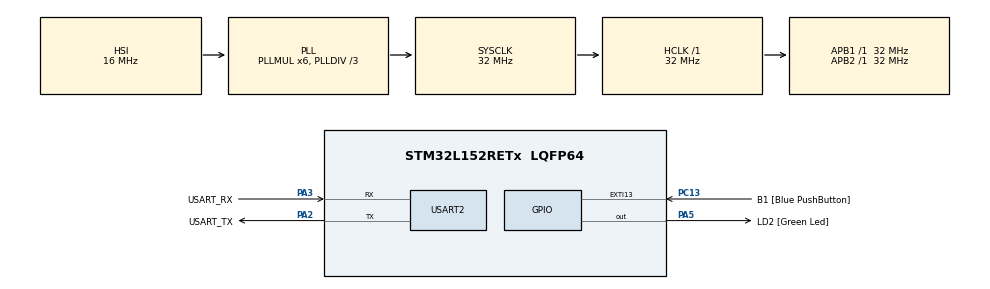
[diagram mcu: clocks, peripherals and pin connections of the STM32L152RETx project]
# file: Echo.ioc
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Mcu.Family=STM32L1
Mcu.Name=STM32L152RETx
Mcu.Package=LQFP64
NVIC.PriorityGroup=NVIC_PRIORITYGROUP_0
PA13.GPIO_Label=TMS
PA13.Mode=Serial_Wire
PA13.Signal=SYS_JTMS-SWDIO
PA14.GPIO_Label=TCK
PA14.Mode=Serial_Wire
PA14.Signal=SYS_JTCK-SWCLK
PA2.GPIO_Label=USART_TX
PA2.Mode=Asynchronous
PA2.Signal=USART2_TX
PA3.GPIO_Label=USART_RX
PA3.Mode=Asynchronous
PA3.Signal=USART2_RX
PA5.GPIO_Label=LD2 [Green Led]
PA5.Signal=GPIO_Output
PB3.GPIO_Label=SWO
PB3.Signal=SYS_JTDO-TRACESWO
PC13-WKUP2.GPIO_Label=B1 [Blue PushButton]
PC13-WKUP2.Signal=GPXTI13
PC14-OSC32_IN.Mode=LSE-External-Oscillator
PC14-OSC32_IN.Signal=RCC_OSC32_IN
PC15-OSC32_OUT.Mode=LSE-External-Oscillator
PC15-OSC32_OUT.Signal=RCC_OSC32_OUT
PH0-OSC_IN.Mode=HSE-External-Clock-Source
PH0-OSC_IN.Signal=RCC_OSC_IN
PH1-OSC_OUT.Signal=RCC_OSC_OUT
ProjectManager.HeapSize=0x200
ProjectManager.StackSize=0x400
ProjectManager.TargetToolchain=STM32CubeIDE
RCC.48MHZClocksFreq_Value=48000000
RCC.AHBFreq_Value=32000000
RCC.APB1Freq_Value=32000000
RCC.APB1TimFreq_Value=32000000
RCC.APB2Freq_Value=32000000
RCC.APB2TimFreq_Value=32000000
RCC.HCLKFreq_Value=32000000
RCC.HSE_VALUE=8000000
RCC.HSI_VALUE=16000000
RCC.MSI_VALUE=2097000
RCC.PLLDIV=RCC_PLL_DIV3
RCC.PLLMUL=RCC_PLL_MUL6
RCC.RTCClockSelectionVirtual=RCC_RTCCLKSOURCE_LSE
RCC.SYSCLKFreq_VALUE=32000000
RCC.SYSCLKSource=RCC_SYSCLKSOURCE_PLLCLK
RCC.USBOutput=48000000
RCC.VCOOutputFreq_Value=96000000
USART2.VirtualMode=VM_ASYNC
board=NUCLEO-L152RE

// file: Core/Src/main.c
/* USER CODE BEGIN Header */
/**
  ******************************************************************************
  * @file           : main.c
  * @brief          : Main program body
  ******************************************************************************
  * @attention
  *
  * Copyright (c) 2023 STMicroelectronics.
  * All rights reserved.
  *
  * This software is licensed under terms that can be found in the LICENSE file
  * in the root directory of this software component.
  * If no LICENSE file comes with this software, it is provided AS-IS.
  *
  ******************************************************************************
  */
/* USER CODE END Header */
#include "main.h"
#include "usart.h"
#include "gpio.h"

void SystemClock_Config(void);

int main(void)
{
  /* USER CODE BEGIN 1 */
	uint8_t rx_data;

  /* USER CODE END 1 */

  /* MCU Configuration--------------------------------------------------------*/

  /* Reset of all peripherals, Initializes the Flash interface and the Systick. */
  HAL_Init();

  /* Configure the system clock */
  SystemClock_Config();

  /* Initialize all configured peripherals */
  MX_GPIO_Init();
  MX_USART2_UART_Init();

  /* Infinite loop */
  /* USER CODE BEGIN WHILE */
  while (1)
  {
	  HAL_UART_Receive(&huart2, &rx_data, 1, HAL_MAX_DELAY);
	  HAL_GPIO_TogglePin(LD2_GPIO_Port, LD2_Pin);
	  HAL_UART_Transmit(&huart2, &rx_data, 1, HAL_MAX_DELAY);
	  HAL_UART_Transmit(&huart2, &rx_data, 1, HAL_MAX_DELAY);
    /* USER CODE END WHILE */

  }
}

void SystemClock_Config(void)
{
  RCC_OscInitTypeDef RCC_OscInitStruct = {0};
  RCC_ClkInitTypeDef RCC_ClkInitStruct = {0};

  /** Configure the main internal regulator output voltage
  */
  __HAL_PWR_VOLTAGESCALING_CONFIG(PWR_REGULATOR_VOLTAGE_SCALE1);

  /** Initializes the RCC Oscillators according to the specified parameters
  * in the RCC_OscInitTypeDef structure.
  */
  RCC_OscInitStruct.OscillatorType = RCC_OSCILLATORTYPE_HSI;
  RCC_OscInitStruct.HSIState = RCC_HSI_ON;
  RCC_OscInitStruct.HSICalibrationValue = RCC_HSICALIBRATION_DEFAULT;
  RCC_OscInitStruct.PLL.PLLState = RCC_PLL_ON;
  RCC_OscInitStruct.PLL.PLLSource = RCC_PLLSOURCE_HSI;
  RCC_OscInitStruct.PLL.PLLMUL = RCC_PLL_MUL6;
  RCC_OscInitStruct.PLL.PLLDIV = RCC_PLL_DIV3;
  if (HAL_RCC_OscConfig(&RCC_OscInitStruct) != HAL_OK)
  {
    Error_Handler();
  }

  /** Initializes the CPU, AHB and APB buses clocks
  */
  RCC_ClkInitStruct.ClockType = RCC_CLOCKTYPE_HCLK|RCC_CLOCKTYPE_SYSCLK
                              |RCC_CLOCKTYPE_PCLK1|RCC_CLOCKTYPE_PCLK2;
  RCC_ClkInitStruct.SYSCLKSource = RCC_SYSCLKSOURCE_PLLCLK;
  RCC_ClkInitStruct.AHBCLKDivider = RCC_SYSCLK_DIV1;
  RCC_ClkInitStruct.APB1CLKDivider = RCC_HCLK_DIV1;
  RCC_ClkInitStruct.APB2CLKDivider = RCC_HCLK_DIV1;

  if (HAL_RCC_ClockConfig(&RCC_ClkInitStruct, FLASH_LATENCY_1) != HAL_OK)
  {
    Error_Handler();
  }
}

void Error_Handler(void)
{
  __disable_irq();
  while (1)
  {
  }
}
